# WKUP_CTRL_MMR0_CFG0 register map
Vendor: Texas Instruments
Peripheral module from a debugger description file (folder J7_AHP).
Registers are 32-bit, read-write, reset 0x0 unless marked. A register's access mark holds for its fields unless they carry their own. Offsets are as the file gives them; lines under a group give offsets from that group; [hi:lo] are bit positions; {n}, {i} and the like mark numbered series; 'fields as' and 'values as' point back to an identical list; <NAME> marks a mode.

## WKUP_CTRL_MMR0_CFG0 (part 1 of 11)
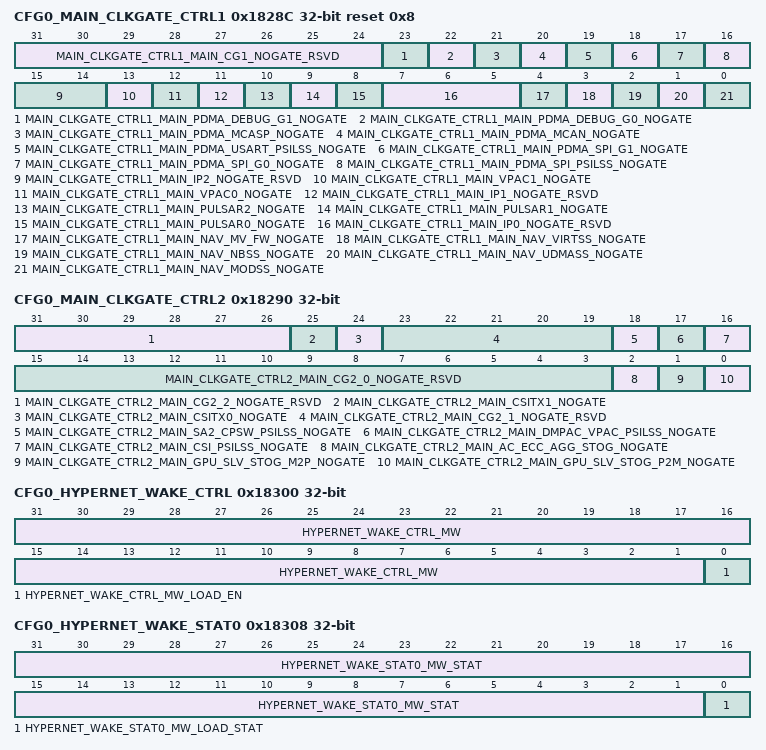
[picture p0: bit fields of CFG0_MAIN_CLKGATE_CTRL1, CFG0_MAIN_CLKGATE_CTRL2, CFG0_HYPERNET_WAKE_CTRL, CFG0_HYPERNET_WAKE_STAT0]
0x1828C CFG0_MAIN_CLKGATE_CTRL1 reset 0x8 — Controls the power clock gating feature of MAIN domain modules and busses
  [31:24] MAIN_CLKGATE_CTRL1_MAIN_CG1_NOGATE_RSVD — MAIN PDMA clock gate disable. These bits should remain unchanged (written only with their default value) to maintain compatibility with future devices. 0 - Clocks are gated on idle for power savings 1 - Clocks are not gated on idle, power saving disabled
  [23] MAIN_CLKGATE_CTRL1_MAIN_PDMA_DEBUG_G1_NOGATE — MAIN domain PDMA Debug_G1 clock gate disable. 0 - Clocks are gated on idle for power savings 1 - Clocks are not gated on idle, power saving disabled
  [22] MAIN_CLKGATE_CTRL1_MAIN_PDMA_DEBUG_G0_NOGATE — MAIN domain PDMA Debug_G0 clock gate disable. 0 - Clocks are gated on idle for power savings 1 - Clocks are not gated on idle, power saving disabled
  [21] MAIN_CLKGATE_CTRL1_MAIN_PDMA_MCASP_NOGATE — MAIN domain PDMA MCASP clock gate disable. 0 - Clocks are gated on idle for power savings 1 - Clocks are not gated on idle, power saving disabled
  [20] MAIN_CLKGATE_CTRL1_MAIN_PDMA_MCAN_NOGATE — MAIN domain PDMA MCAN clock gate disable. 0 - Clocks are gated on idle for power savings 1 - Clocks are not gated on idle, power saving disabled
  [19] MAIN_CLKGATE_CTRL1_MAIN_PDMA_USART_PSILSS_NOGATE — MAIN domain PDMA USART PSILSS clock gate disable. 0 - Clocks are gated on idle for power savings 1 - Clocks are not gated on idle, power saving disabled
  [18] MAIN_CLKGATE_CTRL1_MAIN_PDMA_SPI_G1_NOGATE — MAIN domain PDMA SPI_G1 clock gate disable. 0 - Clocks are gated on idle for power savings 1 - Clocks are not gated on idle, power saving disabled
  [17] MAIN_CLKGATE_CTRL1_MAIN_PDMA_SPI_G0_NOGATE — MAIN domain PDMA SPI_G0 clock gate disable. 0 - Clocks are gated on idle for power savings 1 - Clocks are not gated on idle, power saving disabled
  [16] MAIN_CLKGATE_CTRL1_MAIN_PDMA_SPI_PSILSS_NOGATE — MAIN domain PDMA SPI PSILSS clock gate disable. 0 - Clocks are gated on idle for power savings 1 - Clocks are not gated on idle, power saving disabled
  [15:14] MAIN_CLKGATE_CTRL1_MAIN_IP2_NOGATE_RSVD — MAIN IP reserved clock gate disable. These bits should remain unchanged (written only with their default value) to maintain compatibility with future devices. 0 - Clocks are gated on idle for power savings 1 - Clocks are not gated on idle, power saving disabled
  [13] MAIN_CLKGATE_CTRL1_MAIN_VPAC1_NOGATE — MAIN domain VPAC 1 clock gate disable. 0 - Clocks are gated on idle for power savings 1 - Clocks are not gated on idle, power saving disabled
  [12] MAIN_CLKGATE_CTRL1_MAIN_VPAC0_NOGATE — MAIN domain VPAC 0 clock gate disable. 0 - Clocks are gated on idle for power savings 1 - Clocks are not gated on idle, power saving disabled
  [11] MAIN_CLKGATE_CTRL1_MAIN_IP1_NOGATE_RSVD — MAIN IP reserved clock gate disable. These bits should remain unchanged (written only with their default value) to maintain compatibility with future devices. 0 - Clocks are gated on idle for power savings 1 - Clocks are not gated on idle, power saving disabled
  [10] MAIN_CLKGATE_CTRL1_MAIN_PULSAR2_NOGATE — MAIN domain Pulsar 2 clock gate disable. 0 - Clocks are gated on idle for power savings 1 - Clocks are not gated on idle, power saving disabled
  [9] MAIN_CLKGATE_CTRL1_MAIN_PULSAR1_NOGATE — MAIN domain Pulsar 1 clock gate disable. 0 - Clocks are gated on idle for power savings 1 - Clocks are not gated on idle, power saving disabled
  [8] MAIN_CLKGATE_CTRL1_MAIN_PULSAR0_NOGATE — MAIN domain Pulsar 0 clock gate disable. 0 - Clocks are gated on idle for power savings 1 - Clocks are not gated on idle, power saving disabled
  [7:5] MAIN_CLKGATE_CTRL1_MAIN_IP0_NOGATE_RSVD — MAIN IP reserved clock gate disable. These bits should remain unchanged (written only with their default value) to maintain compatibility with future devices. 0 - Clocks are gated on idle for power savings 1 - Clocks are not gated on idle, power saving disabled
  [4] MAIN_CLKGATE_CTRL1_MAIN_NAV_MV_FW_NOGATE — MAIN NavSS Mod/Virt Firewall interface clock gate disable. 0 - Clocks are gated on idle for power savings 1 - Clocks are not gated on idle, power saving disabled
  [3] MAIN_CLKGATE_CTRL1_MAIN_NAV_VIRTSS_NOGATE — MAIN NavSS VIRTSS interface clock gate disable. 0 - Clocks are gated on idle for power savings 1 - Clocks are not gated on idle, power saving disabled
  [2] MAIN_CLKGATE_CTRL1_MAIN_NAV_NBSS_NOGATE — MAIN NavSS NB interface clock gate disable. 0 - Clocks are gated on idle for power savings 1 - Clocks are not gated on idle, power saving disabled
  [1] MAIN_CLKGATE_CTRL1_MAIN_NAV_UDMASS_NOGATE — Main NavSS UDMA interface clock gate disable. 0 - Clocks are gated on idle for power savings 1 - Clocks are not gated on idle, power saving disabled
  [0] MAIN_CLKGATE_CTRL1_MAIN_NAV_MODSS_NOGATE — MAIN NavSS MODSS interface clock gate disable. 0 - Clocks are gated on idle for power savings 1 - Clocks are not gated on idle, power saving disabled
0x18290 CFG0_MAIN_CLKGATE_CTRL2 — Controls the power clock gating feature of MAIN domain modules and busses
  [31:26] MAIN_CLKGATE_CTRL2_MAIN_CG2_2_NOGATE_RSVD — MAIN domain spare clock gate disable. These bits should remain unchanged (written only with their default value) to maintain compatibility with future devices. 0 - Clocks are gated on idle for power savings 1 - Clocks are not gated on idle, power saving disabled
  [25] MAIN_CLKGATE_CTRL2_MAIN_CSITX1_NOGATE — MAIN domain CSI_TX1 clock gate disable. 0 - Clocks are gated on idle for power savings 1 - Clocks are not gated on idle, power saving disabled
  [24] MAIN_CLKGATE_CTRL2_MAIN_CSITX0_NOGATE — MAIN domain CSI_TX0 clock gate disable. 0 - Clocks are gated on idle for power savings 1 - Clocks are not gated on idle, power saving disabled
  [23:19] MAIN_CLKGATE_CTRL2_MAIN_CG2_1_NOGATE_RSVD — MAIN domain spare clock gate disable. These bits should remain unchanged (written only with their default value) to maintain compatibility with future devices. 0 - Clocks are gated on idle for power savings 1 - Clocks are not gated on idle, power saving disabled
  [18] MAIN_CLKGATE_CTRL2_MAIN_SA2_CPSW_PSILSS_NOGATE — MAIN domain SA2_UL/SPCW PSILSS clock gate disable. 0 - Clocks are gated on idle for power savings 1 - Clocks are not gated on idle, power saving disabled
  [17] MAIN_CLKGATE_CTRL2_MAIN_DMPAC_VPAC_PSILSS_NOGATE — MAIN domain DMPAC/VPAC PSILSS clock gate disable. 0 - Clocks are gated on idle for power savings 1 - Clocks are not gated on idle, power saving disabled
  [16] MAIN_CLKGATE_CTRL2_MAIN_CSI_PSILSS_NOGATE — MAIN domain CSI PSILSS clock gate disable. 0 - Clocks are gated on idle for power savings 1 - Clocks are not gated on idle, power saving disabled
  [15:3] MAIN_CLKGATE_CTRL2_MAIN_CG2_0_NOGATE_RSVD — MAIN domain spare clock gate disable. These bits should remain unchanged (written only with their default value) to maintain compatibility with future devices. 0 - Clocks are gated on idle for power savings 1 - Clocks are not gated on idle, power saving disabled
  [2] MAIN_CLKGATE_CTRL2_MAIN_AC_ECC_AGG_STOG_NOGATE — MAIN domain ac ECC aggregator Slave Timeout Gasket (main_ac_ecc_aggr_stog) clock gate disable. 0 - Clocks are gated on idle for power savings 1 - Clocks are not gated on idle, power saving disabled
  [1] MAIN_CLKGATE_CTRL2_MAIN_GPU_SLV_STOG_M2P_NOGATE — MAIN domain GPU Slave Timeout Gasket output (main_gpu_slv_stog_m2p_pwr_dis) clock gate disable. 0 - Clocks are gated on idle for power savings 1 - Clocks are not gated on idle, power saving disabled
  [0] MAIN_CLKGATE_CTRL2_MAIN_GPU_SLV_STOG_P2M_NOGATE — MAIN domain GPU Slave Timeout Gasket input (main_gpu_slv_stog_p2m_pwr_dis) clock gate disable. 0 - Clocks are gated on idle for power savings 1 - Clocks are not gated on idle, power saving disabled
0x18294 CFG0_MAIN_CLKGATE_CTRL3 — Controls the power clock gating feature of MAIN domain modules and busses
  [31:0] MAIN_CLKGATE_CTRL3_MAIN_CG3_NOGATE_RSVD — MAIN domain spare clock gate disable. These bits should remain unchanged (written only with their default value) to maintain compatibility with future devices. 0 - Clocks are gated on idle for power savings 1 - Clocks are not gated on idle, power saving disabled
0x18300 CFG0_HYPERNET_WAKE_CTRL — Controls the operation of IO wakeup on the MAIN HYPERNET pins
  [31:1] HYPERNET_WAKE_CTRL_MW — HYPERNET IO magic word. This 31-bit value that enables placing of the HYPERNET I/Os into isolation for daisy-chain wakeup operation. 0x2AAAAAAA - Magic word value to enable isolation when qualified with mw_load bit Others - Any other value will prevent isolation when mw_load transitions from 0 to 1.
  [0] HYPERNET_WAKE_CTRL_MW_LOAD_EN — Magic word load enableSetting this bit to 1 loads and locks the mw field for HYPERNET IO isolation. If the mw field matches the magic word value then the value is latched into the HYPERNET IO voltage domain and HYPERNET IO isolation is enabled. 0 - Unlock and do not load mw value for comparison 1 - Load and lock mw for magic word value comparison
0x18308 CFG0_HYPERNET_WAKE_STAT0 ro — Provides the status of MAIN HYPERNET_WAKE control bits
  [31:1] HYPERNET_WAKE_STAT0_MW_STAT — HYPERNET magic word statusIndicates the latched value of the mw field.
  [0] HYPERNET_WAKE_STAT0_MW_LOAD_STAT — Magic word load status.Indicates the latched value of the mw_load_en bit
0x1830C CFG0_HYPERNET_WAKE_STAT1 ro — Provides MAIN HYPERNET IO isolation status
  [0] HYPERNET_WAKE_STAT1_HYPERNET_IO_MODE — Indicates if HYPERNET IO wakeup mode is enabled. 0 - Not enabled (load_en not set or mw doesn't match magic word) 1 - HYPERNET IO mode enabled
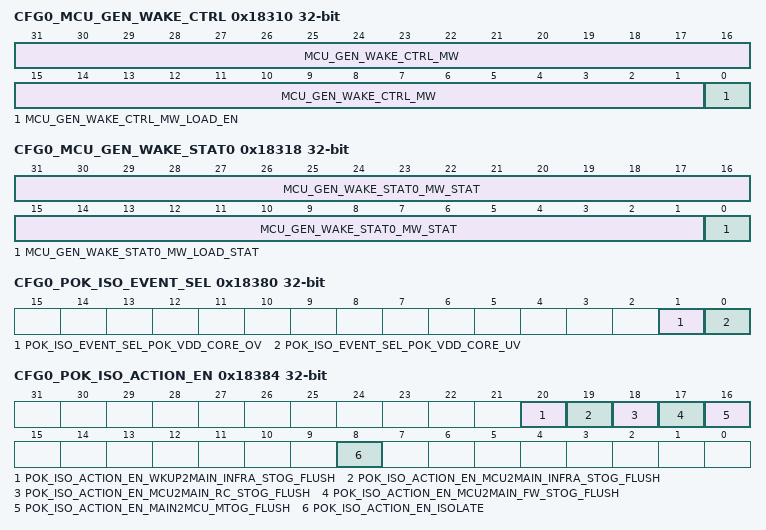
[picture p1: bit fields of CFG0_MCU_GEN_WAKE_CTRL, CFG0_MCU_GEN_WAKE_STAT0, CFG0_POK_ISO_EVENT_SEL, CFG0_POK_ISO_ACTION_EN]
0x18310 CFG0_MCU_GEN_WAKE_CTRL — Controls the operation of IO wakeup on the MCU_GENERAL pins
  [31:1] MCU_GEN_WAKE_CTRL_MW — MCU_GENERAL IO magic word. This 31-bit value that enables placing of the MCU_GENERAL I/Os into isolation for daisy-chain wakeup operation. 0x2AAAAAAA - Magic word value to enable isolation when qualified with mw_load bit Others - Any other value will prevent isolation when mw_load transitions from 0 to 1.
  [0] MCU_GEN_WAKE_CTRL_MW_LOAD_EN — Magic word load enableSetting this bit to 1 loads and locks the mw field for MCU_GENERAL IO isolation. If the mw field matches the magic word value then the value is latched into the MCU_GENERAL IO voltage domain and MCU_GENERAL IO isolation is enabled. 0 - Unlock and do not load mw value for comparison 1 - Load and lock mw for magic word value comparison
0x18318 CFG0_MCU_GEN_WAKE_STAT0 ro — Provides the status of MCU_GEN_WAKE control bits
  [31:1] MCU_GEN_WAKE_STAT0_MW_STAT — MCU_GENERAL magic word statusIndicates the latched value of the mw field.
  [0] MCU_GEN_WAKE_STAT0_MW_LOAD_STAT — Magic word load status.Indicates the latched value of the mw_load_en bit
0x1831C CFG0_MCU_GEN_WAKE_STAT1 ro — Provides MCU_GENERAL IO isolation status
  [0] MCU_GEN_WAKE_STAT1_MCU_GEN_IO_MODE — Indicates if MCU_GENERAL IO wakeup mode is enabled. 0 - Not enabled (load_en not set or mw doesn't match magic word) 1 - MCU_GENERAL IO mode enabled
0x18380 CFG0_POK_ISO_EVENT_SEL — Determines which POK events activate isolation features
  [1] POK_ISO_EVENT_SEL_POK_VDD_CORE_OV — VDD_CORE overvoltage detection triggers enabled isolation actions
  [0] POK_ISO_EVENT_SEL_POK_VDD_CORE_UV — VDD_CORE undervoltage detection triggers enabled isolation actions
0x18384 CFG0_POK_ISO_ACTION_EN — Selects which isolation actions to perform when POK events as selected in POK_ISO_EVENT_SEL occur
  [20] POK_ISO_ACTION_EN_WKUP2MAIN_INFRA_STOG_FLUSH — WKUP to Main INFRA slave timeout gasket flush enable: 0 - Enabled POK events have no effect on this gasket 1 - Enabled POK events will assert the flush for this gasket
  [19] POK_ISO_ACTION_EN_MCU2MAIN_INFRA_STOG_FLUSH — MCU to Main INFRA slave timeout gasket flush enable: 0 - Enabled POK events have no effect on this gasket 1 - Enabled POK events will assert the flush for this gasket
  [18] POK_ISO_ACTION_EN_MCU2MAIN_RC_STOG_FLUSH — MCU to Main RC slave timeout gasket flush enable: 0 - Enabled POK events have no effect on this gasket 1 - Enabled POK events will assert the flush for this gasket
  [17] POK_ISO_ACTION_EN_MCU2MAIN_FW_STOG_FLUSH — MCU to Main FW slave timeout gasket flush enable: 0 - Enabled POK events have no effect on this gasket 1 - Enabled POK events will assert the flush for this gasket
  [16] POK_ISO_ACTION_EN_MAIN2MCU_MTOG_FLUSH — MAIN to MCU master timeout gasket flush enable: 0 - Enabled POK events have no effect on this gasket 1 - Enabled POK events will assert the flush for this gasket
  [8] POK_ISO_ACTION_EN_ISOLATE — If enabled, the isolate signal will be asserted after all enabled flush signals have been asserted for 4 of their respective time-out gasket clocks when any selected POK event occurs. 0 - Isolation is not asserted on selected POK event 1 - Isolation signal is asserted on selected POK event after enabled TOG flush
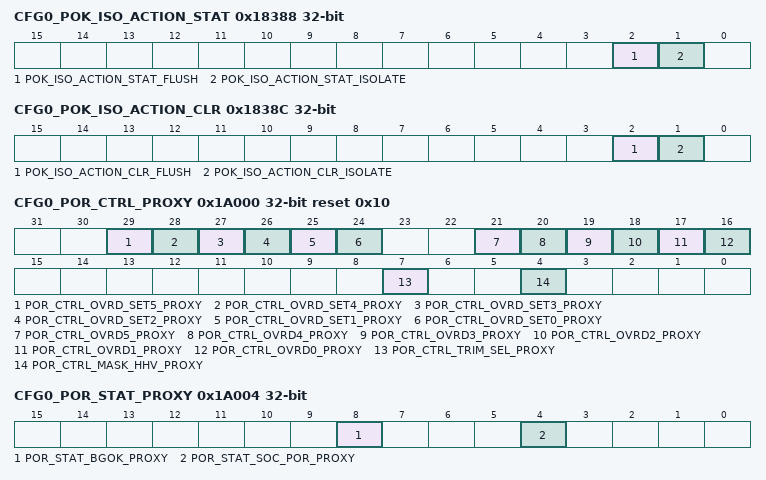
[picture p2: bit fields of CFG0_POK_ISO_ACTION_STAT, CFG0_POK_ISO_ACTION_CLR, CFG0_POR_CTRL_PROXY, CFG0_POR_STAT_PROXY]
0x18388 CFG0_POK_ISO_ACTION_STAT ro — Indicates the status of enabled POK isolation actions
  [2] POK_ISO_ACTION_STAT_FLUSH — POK activated timeout gasket flush statusThis signal will remain asserted until a 1 is written to the POK_ISO_ACTION_CLR_flush bit. 0 - No gasket flush is being asserted by enabled POK event 1 - Enabled gasket flush signals are being asserted due to an enabled POK event
  [1] POK_ISO_ACTION_STAT_ISOLATE — POK activated Isolate statusThis signal will remain asserted until a 1 is written to the POK_ISO_ACTION_CLR_isolate bit. 0 - No isolate is being asserted by enabled POK event 1 - Isolate signal is being asserted due to an enabled POK event
0x1838C CFG0_POK_ISO_ACTION_CLR — Selects which active POK isolation actions to clear
  [2] POK_ISO_ACTION_CLR_FLUSH — POK activated timeout gasket flush clearAlways read as 0. Writing 1 deasserts POK activated timeot gasket flush signals. 0 - Writing 0 has no effect. Bit always reads as 0 1 - Deassert gasket flush signals. Bit will clear to 0 after write.
  [1] POK_ISO_ACTION_CLR_ISOLATE — POK activated isolate clearAlways read as 0. Writing 1 deasserts POK activated isolate signal. 0 - Writing 0 has no effect. Bit always reads as 0 1 - Deassert isolate signal. Bit will clear to 0 after write.
{0x19100+4i} CFG0_CLAIMREG_P6_R{i}_READONLY ro (i=0..7)
  [31:0] CLAIMREG_P6_R{i}_READONLY — Claim bits for Partition 6
0x1A000 CFG0_POR_CTRL_PROXY reset 0x10 — Configures POR module reset behavior
  [29] POR_CTRL_OVRD_SET5_PROXY — Reserved override set
  [28] POR_CTRL_OVRD_SET4_PROXY — POKLVB override set
  [27] POR_CTRL_OVRD_SET3_PROXY — POKLVA override set
  [26] POR_CTRL_OVRD_SET2_PROXY — POKHV override set
  [25] POR_CTRL_OVRD_SET1_PROXY — BGOK override set
  [24] POR_CTRL_OVRD_SET0_PROXY — PORHV override set
  [21] POR_CTRL_OVRD5_PROXY — Reserved override enable
  [20] POR_CTRL_OVRD4_PROXY — POKLVB override enable
  [19] POR_CTRL_OVRD3_PROXY — POKLVA override enable
  [18] POR_CTRL_OVRD2_PROXY — POKHV override enable
  [17] POR_CTRL_OVRD1_PROXY — BGOK override enable
  [16] POR_CTRL_OVRD0_PROXY — PORHV override enable
  [7] POR_CTRL_TRIM_SEL_PROXY — POR Trim Select 0 - Trim selections for Bandgap and POKs come from HHV defaults 1 - Trim selections for Bandgap and POKs come from POR_BANDGAP_CTRL and POR_POKxxx_CTRL registers
  [4] POR_CTRL_MASK_HHV_PROXY — Mask HHV/SOC_PORz outputs when applying new trim values
0x1A004 CFG0_POR_STAT_PROXY ro — Shows POR module status
  [8] POR_STAT_BGOK_PROXY — Bandgap OK status
  [4] POR_STAT_SOC_POR_PROXY — POR module status 0 - Module is in functional mode 1 - Module is in reset mode
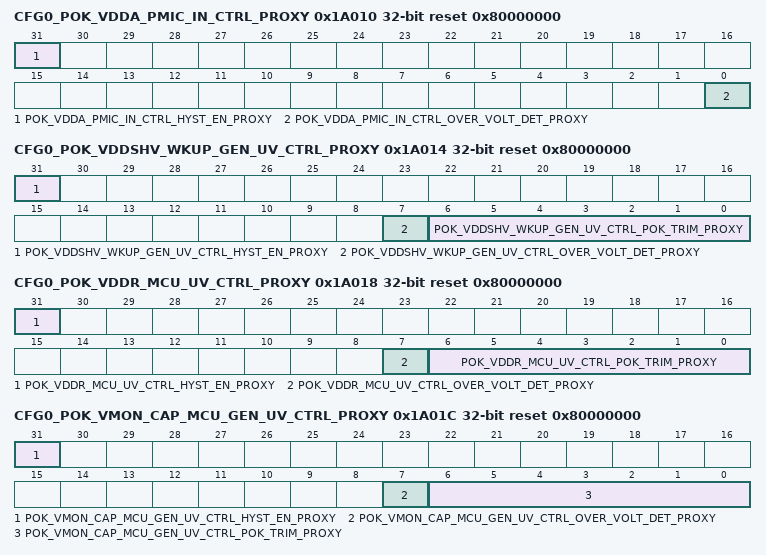
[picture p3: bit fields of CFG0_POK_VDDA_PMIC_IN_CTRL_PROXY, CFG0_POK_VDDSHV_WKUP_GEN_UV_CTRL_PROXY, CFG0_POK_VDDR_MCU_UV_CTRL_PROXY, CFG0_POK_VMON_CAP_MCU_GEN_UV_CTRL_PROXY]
0x1A010 CFG0_POK_VDDA_PMIC_IN_CTRL_PROXY reset 0x80000000 — Controls operation of the VDDA_PMIC_IN POK module
  [31] POK_VDDA_PMIC_IN_CTRL_HYST_EN_PROXY — Enable POK hysteresis
  [0] POK_VDDA_PMIC_IN_CTRL_OVER_VOLT_DET_PROXY — Over / under voltage detection mode 0 - Under voltage detection 1 - Over voltage detection
0x1A014 CFG0_POK_VDDSHV_WKUP_GEN_UV_CTRL_PROXY reset 0x80000000 — Controls operation of the VDDSHV_WKUP_GENERAL POK undervoltage detection
  [31] POK_VDDSHV_WKUP_GEN_UV_CTRL_HYST_EN_PROXY — Enable POK hysteresis
  [7] POK_VDDSHV_WKUP_GEN_UV_CTRL_OVER_VOLT_DET_PROXY — Over / under voltage detection mode 0 - Under voltage detection 1 - Over voltage detection
  [6:0] POK_VDDSHV_WKUP_GEN_UV_CTRL_POK_TRIM_PROXY — POK trim bits. These bits are used to trim the comparator threshold voltage. See POK spec and J7 efuse spec for details
0x1A018 CFG0_POK_VDDR_MCU_UV_CTRL_PROXY reset 0x80000000 — Controls operation of the VDDR_MCU POK undervoltage detection
  [31] POK_VDDR_MCU_UV_CTRL_HYST_EN_PROXY — Enable POK hysteresis
  [7] POK_VDDR_MCU_UV_CTRL_OVER_VOLT_DET_PROXY — Over / under voltage detection mode 0 - Under voltage detection 1 - Over voltage detection
  [6:0] POK_VDDR_MCU_UV_CTRL_POK_TRIM_PROXY — POK trim bits. These bits are used to trim the comparator threshold voltage. See POK spec and J7 efuse spec for details
0x1A01C CFG0_POK_VMON_CAP_MCU_GEN_UV_CTRL_PROXY reset 0x80000000 — Controls operation of the VMON_CAP_MCU_GENERAL POK undervoltage detection
  [31] POK_VMON_CAP_MCU_GEN_UV_CTRL_HYST_EN_PROXY — Enable POK hysteresis
  [7] POK_VMON_CAP_MCU_GEN_UV_CTRL_OVER_VOLT_DET_PROXY — Over / under voltage detection mode 0 - Under voltage detection 1 - Over voltage detection
  [6:0] POK_VMON_CAP_MCU_GEN_UV_CTRL_POK_TRIM_PROXY — POK trim bits. These bits are used to trim the comparator threshold voltage. See POK spec and efuse spec for details
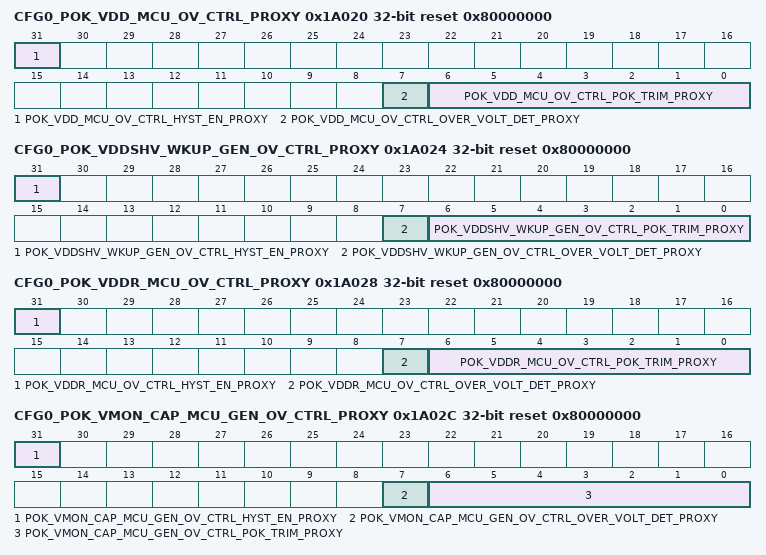
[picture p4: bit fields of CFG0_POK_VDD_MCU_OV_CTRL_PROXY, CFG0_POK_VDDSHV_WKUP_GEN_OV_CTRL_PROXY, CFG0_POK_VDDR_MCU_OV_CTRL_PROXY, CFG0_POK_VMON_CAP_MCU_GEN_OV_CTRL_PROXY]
0x1A020 CFG0_POK_VDD_MCU_OV_CTRL_PROXY reset 0x80000000 — Controls operation of the VDD_MCU overvoltage POK module
  [31] POK_VDD_MCU_OV_CTRL_HYST_EN_PROXY — Enable POK hysteresis
  [7] POK_VDD_MCU_OV_CTRL_OVER_VOLT_DET_PROXY — Over / under voltage detection mode 0 - Under voltage detection 1 - Over voltage detection
  [6:0] POK_VDD_MCU_OV_CTRL_POK_TRIM_PROXY — POK trim bits. These bits are used to trim the comparator threshold voltage. See POK spec and J7 efuse spec for details
0x1A024 CFG0_POK_VDDSHV_WKUP_GEN_OV_CTRL_PROXY reset 0x80000000 — Controls operation of the VDDSHV_WKUP_GENERAL POK overvoltage detection
  [31] POK_VDDSHV_WKUP_GEN_OV_CTRL_HYST_EN_PROXY — Enable POK hysteresis
  [7] POK_VDDSHV_WKUP_GEN_OV_CTRL_OVER_VOLT_DET_PROXY — Over / under voltage detection mode 0 - Under voltage detection 1 - Over voltage detection
  [6:0] POK_VDDSHV_WKUP_GEN_OV_CTRL_POK_TRIM_PROXY — POK trim bits. These bits are used to trim the comparator threshold voltage. See POK spec and J7 efuse spec for details
0x1A028 CFG0_POK_VDDR_MCU_OV_CTRL_PROXY reset 0x80000000 — Controls operation of the VDDR_MCU POK overvoltage detection
  [31] POK_VDDR_MCU_OV_CTRL_HYST_EN_PROXY — Enable POK hysteresis
  [7] POK_VDDR_MCU_OV_CTRL_OVER_VOLT_DET_PROXY — Over / under voltage detection mode 0 - Under voltage detection 1 - Over voltage detection
  [6:0] POK_VDDR_MCU_OV_CTRL_POK_TRIM_PROXY — POK trim bits. These bits are used to trim the comparator threshold voltage. See POK spec and J7 efuse spec for details
0x1A02C CFG0_POK_VMON_CAP_MCU_GEN_OV_CTRL_PROXY reset 0x80000000 — Controls operation of the VMON_CAP_MCU_GENERAL POK overvoltage detection
  [31] POK_VMON_CAP_MCU_GEN_OV_CTRL_HYST_EN_PROXY — Enable POK hysteresis
  [7] POK_VMON_CAP_MCU_GEN_OV_CTRL_OVER_VOLT_DET_PROXY — Over / under voltage detection mode 0 - Under voltage detection 1 - Over voltage detection
  [6:0] POK_VMON_CAP_MCU_GEN_OV_CTRL_POK_TRIM_PROXY — POK trim bits. These bits are used to trim the comparator threshold voltage. See POK spec and efuse spec for details
0x1A070 CFG0_MAIN_VDOM_CTRL_PROXY — Provides MAIN voltage domain isolation for deep sleep operation
  [0] MAIN_VDOM_CTRL_MAIN_VD_OFF_PROXY — MAIN deep sleep isolation enable. This bit should be set prior to powering off the MAIN voltage domain to ensure proper signal isolation.
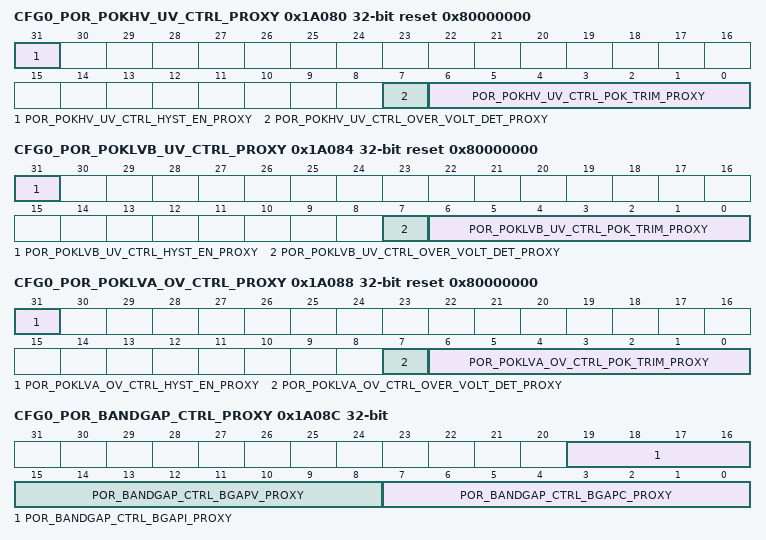
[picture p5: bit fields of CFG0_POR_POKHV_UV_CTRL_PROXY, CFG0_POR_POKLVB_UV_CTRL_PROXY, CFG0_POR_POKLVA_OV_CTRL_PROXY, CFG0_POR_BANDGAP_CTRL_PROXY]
0x1A080 CFG0_POR_POKHV_UV_CTRL_PROXY reset 0x80000000 — Controls operation of the 1.8V VDDA_MCU undervoltage POK within the POR
  [31] POR_POKHV_UV_CTRL_HYST_EN_PROXY — Enable POK hysteresis
  [7] POR_POKHV_UV_CTRL_OVER_VOLT_DET_PROXY — Over / under voltage detection mode 0 - Under voltage detection 1 - Over voltage detection
  [6:0] POR_POKHV_UV_CTRL_POK_TRIM_PROXY — POK trim bits. These bits are used to trim the comparator threshold voltage. See POK spec and J7 efuse spec for details
0x1A084 CFG0_POR_POKLVB_UV_CTRL_PROXY reset 0x80000000 — Controls operation of the VDD_MCU undervoltage POK within the POR
  [31] POR_POKLVB_UV_CTRL_HYST_EN_PROXY — Enable POK hysteresis
  [7] POR_POKLVB_UV_CTRL_OVER_VOLT_DET_PROXY — Over / under voltage detection mode 0 - Under voltage detection 1 - Over voltage detection
  [6:0] POR_POKLVB_UV_CTRL_POK_TRIM_PROXY — POK trim bits. These bits are used to trim the comparator threshold voltage. See POK spec and J7 efuse spec for details
0x1A088 CFG0_POR_POKLVA_OV_CTRL_PROXY reset 0x80000000 — Controls operation of the 1.8V VDDA_MCU overvoltage POK within the POR
  [31] POR_POKLVA_OV_CTRL_HYST_EN_PROXY — Enable POK hysteresis
  [7] POR_POKLVA_OV_CTRL_OVER_VOLT_DET_PROXY — Over / under voltage detection mode 0 - Under voltage detection 1 - Over voltage detection
  [6:0] POR_POKLVA_OV_CTRL_POK_TRIM_PROXY — POK trim bits. These bits are used to trim the comparator threshold voltage. See POK spec and J7 efuse spec for details
0x1A08C CFG0_POR_BANDGAP_CTRL_PROXY — Controls the operation of the bandgap module within the POR
  [19:16] POR_BANDGAP_CTRL_BGAPI_PROXY — Bandgap output current trim bits
  [15:8] POR_BANDGAP_CTRL_BGAPV_PROXY — Bandgap output voltage magnitude trim bits
  [7:0] POR_BANDGAP_CTRL_BGAPC_PROXY — Bandgap slope trim bits. Bit7 is used to calculate the offset
0x1A0A0 CFG0_TEMP_DIODE_TRIM_PROXY — Trims the silicon junction temperature diode calculation
  [13:0] TEMP_DIODE_TRIM_TRIM_PROXY — Sets the diode non-ideality factor (n), starting from 100th place decimal and going down
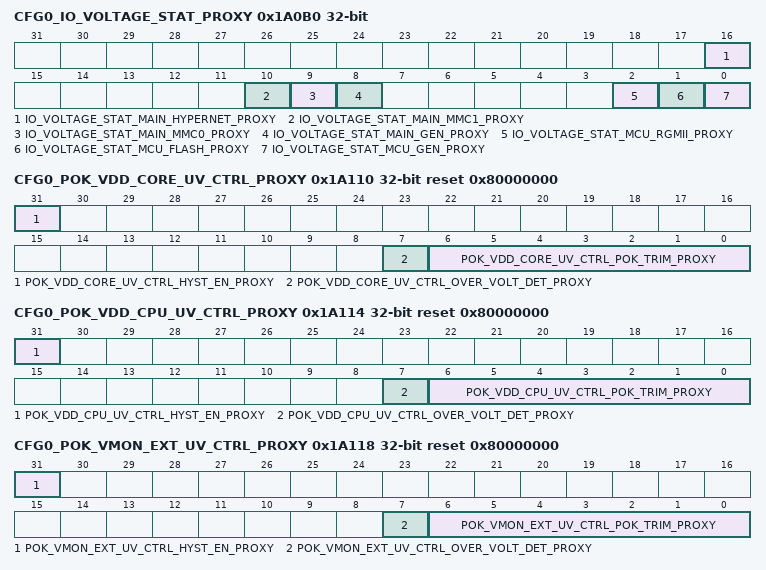
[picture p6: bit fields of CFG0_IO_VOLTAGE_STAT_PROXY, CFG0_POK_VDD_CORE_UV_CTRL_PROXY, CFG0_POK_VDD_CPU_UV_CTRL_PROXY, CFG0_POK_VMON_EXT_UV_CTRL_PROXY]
0x1A0B0 CFG0_IO_VOLTAGE_STAT_PROXY ro — Indicates the I/O voltage of each LVCMOS dual I/O group
  [16] IO_VOLTAGE_STAT_MAIN_HYPERNET_PROXY — Indicates the voltage for the HYPERNET I/O group 0 - I/O group is set for 3.3 V 1 - I/O group is set for 1.8 V
  [10] IO_VOLTAGE_STAT_MAIN_MMC1_PROXY — Indicates the voltage for the MMC1 I/O group 0 - I/O group is set for 3.3 V 1 - I/O group is set for 1.8 V
  [9] IO_VOLTAGE_STAT_MAIN_MMC0_PROXY — Indicates the voltage for the MMC0 I/O group 0 - I/O group is set for 3.3 V 1 - I/O group is set for 1.8 V
  [8] IO_VOLTAGE_STAT_MAIN_GEN_PROXY — Indicates the voltage for the General I/O group 0 - I/O group is set for 3.3 V 1 - I/O group is set for 1.8 V
  [2] IO_VOLTAGE_STAT_MCU_RGMII_PROXY — Indicates the voltage for the MCU CPSW2G RGMII I/O group 0 - I/O group is set for 3.3 V 1 - I/O group is set for 1.8 V
  [1] IO_VOLTAGE_STAT_MCU_FLASH_PROXY — Indicates the voltage for the MCU Flash I/O group 0 - I/O group is set for 3.3 V 1 - I/O group is set for 1.8 V
  [0] IO_VOLTAGE_STAT_MCU_GEN_PROXY — Indicates the voltage for the MCU General I/O group 0 - I/O group is set for 3.3 V 1 - I/O group is set for 1.8 V
0x1A104 CFG0_MAIN_POR_TO_CTRL_PROXY — Indicates the MAIN PORz timeout period
  [2:0] MAIN_POR_TO_CTRL_TIMEOUT_PER_PROXY — MAIN PORz hardware timeout period.During normal operation, the assertion of a MAIN Domain PORz generates a reset request interrupt to the DMSC. The DMSC then performs steps to properly isolate the MAIN Domain before the actual reset is performed. A hardware timeout mechanism is provided to ensure that the PORz gets propagated to the MAIN Domain in the event that a error prevents the DMSC from completing the reset isolation. Field values (Others are reserved): 3'b000 - Immediate 3'b001 - 100 microsec 3'b010 - 200 microsec 3'b011 - 300 microsec 3'b100 - 400 microsec 3'b101 - 500 microsec
0x1A110 CFG0_POK_VDD_CORE_UV_CTRL_PROXY reset 0x80000000 — Controls operation of the VDD_CORE POK undervoltage detection
  [31] POK_VDD_CORE_UV_CTRL_HYST_EN_PROXY — Enable POK hysteresis
  [7] POK_VDD_CORE_UV_CTRL_OVER_VOLT_DET_PROXY — Over / under voltage detection mode 0 - Under voltage detection 1 - Over voltage detection
  [6:0] POK_VDD_CORE_UV_CTRL_POK_TRIM_PROXY — POK trim bits. These bits are used to trim the comparator threshold voltage. See POK spec and efuse spec for details
0x1A114 CFG0_POK_VDD_CPU_UV_CTRL_PROXY reset 0x80000000 — Controls operation of the VDD_CPU POK undervoltage detection
  [31] POK_VDD_CPU_UV_CTRL_HYST_EN_PROXY — Enable POK hysteresis
  [7] POK_VDD_CPU_UV_CTRL_OVER_VOLT_DET_PROXY — Over / under voltage detection mode 0 - Under voltage detection 1 - Over voltage detection
  [6:0] POK_VDD_CPU_UV_CTRL_POK_TRIM_PROXY — POK trim bits. These bits are used to trim the comparator threshold voltage. See POK spec and efuse spec for details
0x1A118 CFG0_POK_VMON_EXT_UV_CTRL_PROXY reset 0x80000000 — Controls operation of the VMON_EXTC POK undervoltage detection
  [31] POK_VMON_EXT_UV_CTRL_HYST_EN_PROXY — Enable POK hysteresis
  [7] POK_VMON_EXT_UV_CTRL_OVER_VOLT_DET_PROXY — Over / under voltage detection mode 0 - Under voltage detection 1 - Over voltage detection
  [6:0] POK_VMON_EXT_UV_CTRL_POK_TRIM_PROXY — POK trim bits. These bits are used to trim the comparator threshold voltage. See POK spec and efuse spec for details
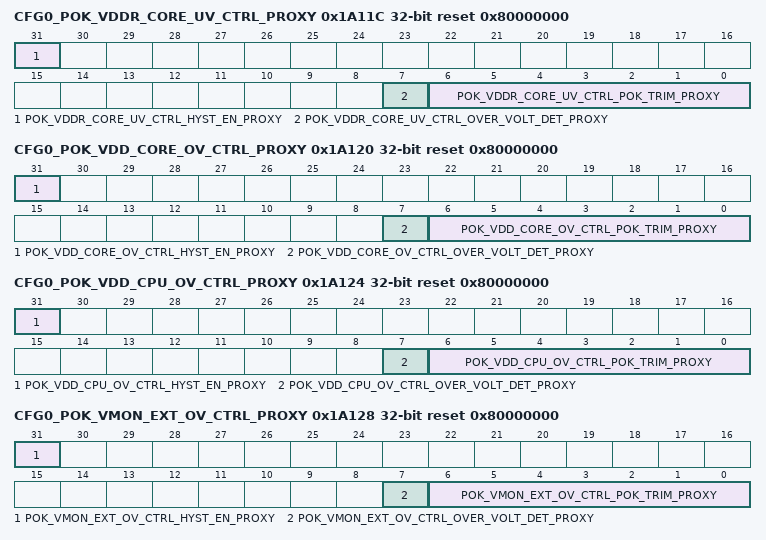
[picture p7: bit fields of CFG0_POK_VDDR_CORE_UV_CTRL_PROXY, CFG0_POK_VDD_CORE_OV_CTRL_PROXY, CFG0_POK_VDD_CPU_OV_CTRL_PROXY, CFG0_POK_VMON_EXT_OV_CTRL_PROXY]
0x1A11C CFG0_POK_VDDR_CORE_UV_CTRL_PROXY reset 0x80000000 — Controls operation of the VDDR_CORE POK undervoltage detection
  [31] POK_VDDR_CORE_UV_CTRL_HYST_EN_PROXY — Enable POK hysteresis
  [7] POK_VDDR_CORE_UV_CTRL_OVER_VOLT_DET_PROXY — Over / under voltage detection mode 0 - Under voltage detection 1 - Over voltage detection
  [6:0] POK_VDDR_CORE_UV_CTRL_POK_TRIM_PROXY — POK trim bits. These bits are used to trim the comparator threshold voltage. See POK spec and efuse spec for details
0x1A120 CFG0_POK_VDD_CORE_OV_CTRL_PROXY reset 0x80000000 — Controls operation of the VDD_CORE POK overvoltage detection
  [31] POK_VDD_CORE_OV_CTRL_HYST_EN_PROXY — Enable POK hysteresis
  [7] POK_VDD_CORE_OV_CTRL_OVER_VOLT_DET_PROXY — Over / under voltage detection mode 0 - Under voltage detection 1 - Over voltage detection
  [6:0] POK_VDD_CORE_OV_CTRL_POK_TRIM_PROXY — POK trim bits. These bits are used to trim the comparator threshold voltage. See POK spec and efuse spec for details
0x1A124 CFG0_POK_VDD_CPU_OV_CTRL_PROXY reset 0x80000000 — Controls operation of the VDD_CPU POK overvoltage detection
  [31] POK_VDD_CPU_OV_CTRL_HYST_EN_PROXY — Enable POK hysteresis
  [7] POK_VDD_CPU_OV_CTRL_OVER_VOLT_DET_PROXY — Over / under voltage detection mode 0 - Under voltage detection 1 - Over voltage detection
  [6:0] POK_VDD_CPU_OV_CTRL_POK_TRIM_PROXY — POK trim bits. These bits are used to trim the comparator threshold voltage. See POK spec and efuse spec for details
0x1A128 CFG0_POK_VMON_EXT_OV_CTRL_PROXY reset 0x80000000 — Controls operation of the VMON_EXT POK overvoltage detection
  [31] POK_VMON_EXT_OV_CTRL_HYST_EN_PROXY — Enable POK hysteresis
  [7] POK_VMON_EXT_OV_CTRL_OVER_VOLT_DET_PROXY — Over / under voltage detection mode 0 - Under voltage detection 1 - Over voltage detection
  [6:0] POK_VMON_EXT_OV_CTRL_POK_TRIM_PROXY — POK trim bits. These bits are used to trim the comparator threshold voltage. See POK spec and efuse spec for details
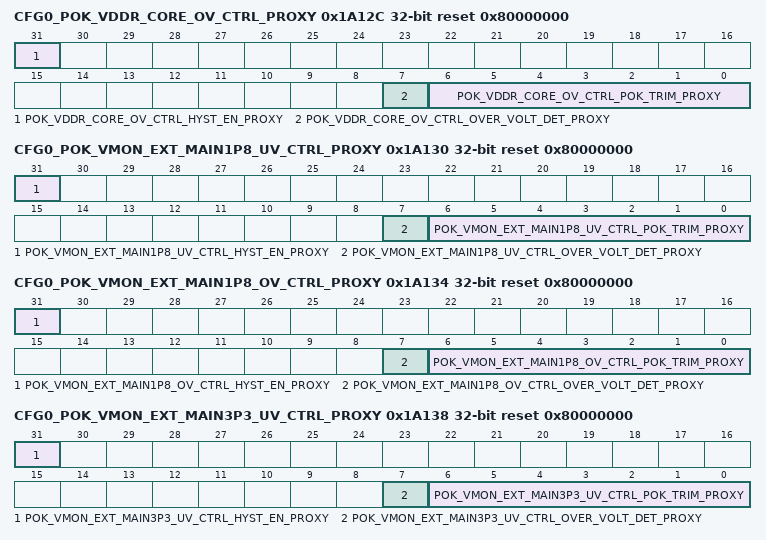
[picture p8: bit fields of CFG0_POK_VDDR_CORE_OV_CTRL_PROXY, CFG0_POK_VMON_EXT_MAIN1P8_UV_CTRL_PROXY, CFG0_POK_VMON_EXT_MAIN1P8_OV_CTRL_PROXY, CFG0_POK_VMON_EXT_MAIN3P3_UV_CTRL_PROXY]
0x1A12C CFG0_POK_VDDR_CORE_OV_CTRL_PROXY reset 0x80000000 — Controls operation of the VDDR_CORE POK overvoltage detection
  [31] POK_VDDR_CORE_OV_CTRL_HYST_EN_PROXY — Enable POK hysteresis
  [7] POK_VDDR_CORE_OV_CTRL_OVER_VOLT_DET_PROXY — Over / under voltage detection mode 0 - Under voltage detection 1 - Over voltage detection
  [6:0] POK_VDDR_CORE_OV_CTRL_POK_TRIM_PROXY — POK trim bits. These bits are used to trim the comparator threshold voltage. See POK spec and efuse spec for details
0x1A130 CFG0_POK_VMON_EXT_MAIN1P8_UV_CTRL_PROXY reset 0x80000000 — Controls operation of the VMON_EXT_MAIN1P8 POK undervoltage detection
  [31] POK_VMON_EXT_MAIN1P8_UV_CTRL_HYST_EN_PROXY — Enable POK hysteresis
  [7] POK_VMON_EXT_MAIN1P8_UV_CTRL_OVER_VOLT_DET_PROXY — Over / under voltage detection mode 0 - Under voltage detection 1 - Over voltage detection
  [6:0] POK_VMON_EXT_MAIN1P8_UV_CTRL_POK_TRIM_PROXY — POK trim bits. These bits are used to trim the comparator threshold voltage. See POK spec and efuse spec for details
0x1A134 CFG0_POK_VMON_EXT_MAIN1P8_OV_CTRL_PROXY reset 0x80000000 — Controls operation of the VMON_EXT_MAIN1P8 POK overvoltage detection
  [31] POK_VMON_EXT_MAIN1P8_OV_CTRL_HYST_EN_PROXY — Enable POK hysteresis
  [7] POK_VMON_EXT_MAIN1P8_OV_CTRL_OVER_VOLT_DET_PROXY — Over / under voltage detection mode 0 - Under voltage detection 1 - Over voltage detection
  [6:0] POK_VMON_EXT_MAIN1P8_OV_CTRL_POK_TRIM_PROXY — POK trim bits. These bits are used to trim the comparator threshold voltage. See POK spec and efuse spec for details
0x1A138 CFG0_POK_VMON_EXT_MAIN3P3_UV_CTRL_PROXY reset 0x80000000 — Controls operation of the VMON_EXT_MAIN3P3 POK undervoltage detection
  [31] POK_VMON_EXT_MAIN3P3_UV_CTRL_HYST_EN_PROXY — Enable POK hysteresis
  [7] POK_VMON_EXT_MAIN3P3_UV_CTRL_OVER_VOLT_DET_PROXY — Over / under voltage detection mode 0 - Under voltage detection 1 - Over voltage detection
  [6:0] POK_VMON_EXT_MAIN3P3_UV_CTRL_POK_TRIM_PROXY — POK trim bits. These bits are used to trim the comparator threshold voltage. See POK spec and efuse spec for details
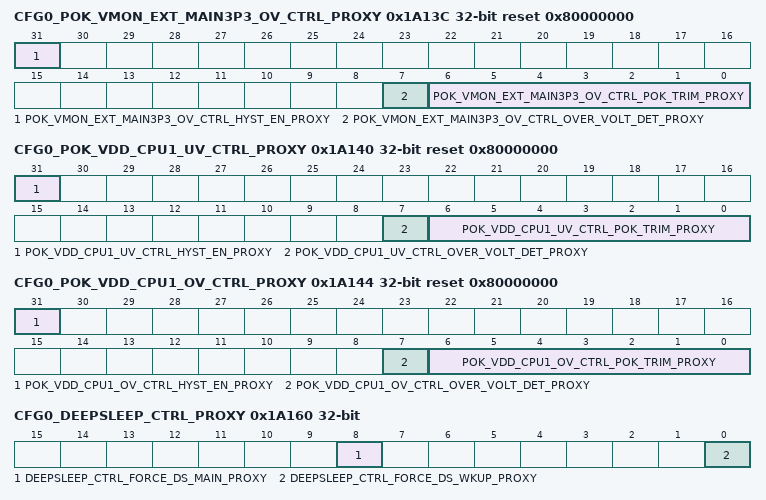
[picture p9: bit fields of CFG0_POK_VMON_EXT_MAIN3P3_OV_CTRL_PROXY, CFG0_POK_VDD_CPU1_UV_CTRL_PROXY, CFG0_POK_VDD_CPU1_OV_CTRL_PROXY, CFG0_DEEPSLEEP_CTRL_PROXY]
0x1A13C CFG0_POK_VMON_EXT_MAIN3P3_OV_CTRL_PROXY reset 0x80000000 — Controls operation of the VMON_EXT_MAIN3P3 POK overvoltage detection
  [31] POK_VMON_EXT_MAIN3P3_OV_CTRL_HYST_EN_PROXY — Enable POK hysteresis
  [7] POK_VMON_EXT_MAIN3P3_OV_CTRL_OVER_VOLT_DET_PROXY — Over / under voltage detection mode 0 - Under voltage detection 1 - Over voltage detection
  [6:0] POK_VMON_EXT_MAIN3P3_OV_CTRL_POK_TRIM_PROXY — POK trim bits. These bits are used to trim the comparator threshold voltage. See POK spec and efuse spec for details
0x1A140 CFG0_POK_VDD_CPU1_UV_CTRL_PROXY reset 0x80000000 — Controls operation of the VDD_DDR0 POK undervoltage detection
  [31] POK_VDD_CPU1_UV_CTRL_HYST_EN_PROXY — Enable POK hysteresis
  [7] POK_VDD_CPU1_UV_CTRL_OVER_VOLT_DET_PROXY — Over / under voltage detection mode 0 - Under voltage detection 1 - Over voltage detection
  [6:0] POK_VDD_CPU1_UV_CTRL_POK_TRIM_PROXY — POK trim bits. These bits are used to trim the comparator threshold voltage. See POK spec and efuse spec for details
0x1A144 CFG0_POK_VDD_CPU1_OV_CTRL_PROXY reset 0x80000000 — Controls operation of the VDD_DDR0 POK overvoltage detection
  [31] POK_VDD_CPU1_OV_CTRL_HYST_EN_PROXY — Enable POK hysteresis
  [7] POK_VDD_CPU1_OV_CTRL_OVER_VOLT_DET_PROXY — Over / under voltage detection mode 0 - Under voltage detection 1 - Over voltage detection
  [6:0] POK_VDD_CPU1_OV_CTRL_POK_TRIM_PROXY — POK trim bits. These bits are used to trim the comparator threshold voltage. See POK spec and efuse spec for details
0x1A160 CFG0_DEEPSLEEP_CTRL_PROXY — Used to control IO deepsleep operation
  [8] DEEPSLEEP_CTRL_FORCE_DS_MAIN_PROXY — Force all MAIN IOs into deepsleep mode when set
  [0] DEEPSLEEP_CTRL_FORCE_DS_WKUP_PROXY — Force all WKUP IOs into deepsleep mode when set
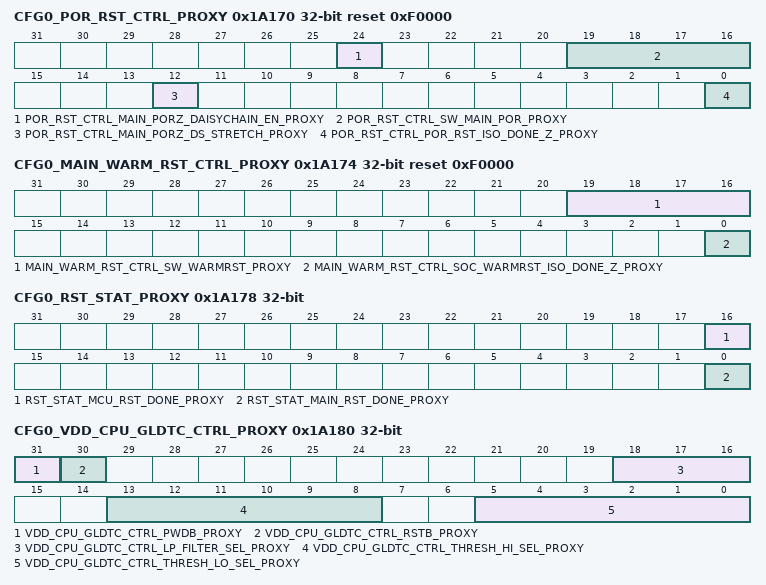
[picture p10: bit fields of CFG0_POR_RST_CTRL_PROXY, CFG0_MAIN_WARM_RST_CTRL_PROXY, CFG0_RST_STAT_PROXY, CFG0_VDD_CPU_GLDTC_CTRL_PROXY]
0x1A170 CFG0_POR_RST_CTRL_PROXY reset 0xF0000 — Controls MAIN domain power-on reset behavior.
  [24] POR_RST_CTRL_MAIN_PORZ_DAISYCHAIN_EN_PROXY — MAIN PORz daisy-chain event enable.Determines if MAIN PORz reset events affect daisy-chain wakeup 0 - DeepSleep MAIN PORz event is not part of daisy-chain 1 - DeepSleep MAIN PORz event is combined w/ other daisy chain events.
  [19:16] POR_RST_CTRL_SW_MAIN_POR_PROXY — Main Domain software power-on reset. When set to 4'b0110, a power-on is issued to the MAIN voltage domain. (Bits will reset to 4'b1111 on reset of the Main Domain)
  [12] POR_RST_CTRL_MAIN_PORZ_DS_STRETCH_PROXY — DeepSleep mode MAIN PORz stretch. 0 - No stretching 1 - Stretch the Main PORz event captured during DeepSleep mode
  [0] POR_RST_CTRL_POR_RST_ISO_DONE_Z_PROXY — Reset isolation completion (active low). This bit should be cleared only after reset isolation of the MAIN domain is complete. 0 - POR reset propagates to MAIN domain 1 - POR reset blocked from MAIN domain
0x1A174 CFG0_MAIN_WARM_RST_CTRL_PROXY reset 0xF0000 — Controls warm reset propagation to the MAIN domain. This allows the SMS to ensure that the MCU domain is properly isolated before the MAIN domain is reset.
  [19:16] MAIN_WARM_RST_CTRL_SW_WARMRST_PROXY — Main Domain software warm reset. When set to 4'b0110, a warm reset is issued to the MAIN voltage domain. (Bits will reset to 4'b1111 on reset of the Main Domain)
  [0] MAIN_WARM_RST_CTRL_SOC_WARMRST_ISO_DONE_Z_PROXY — Reset isolation completion (active low). This bit should be cleared only after reset isolation of the MAIN domain is complete. 0 - Warm reset propagates to MAIN domain 1 - Warm reset blocked from MAIN domain
0x1A178 CFG0_RST_STAT_PROXY ro — Shows the reset status
  [16] RST_STAT_MCU_RST_DONE_PROXY — Indicates MCU domain reset status. 0 - MCU domain is in reset 1 - MCU domain reset is complete
  [0] RST_STAT_MAIN_RST_DONE_PROXY — Indicates MAIN domain Warm reset status. 0 - MAIN domain is in Warm reset 1 - MAIN domain Warm reset is complete
0x1A17C CFG0_MCU_WARM_RST_CTRL_PROXY reset 0xF0000 — Controls warm reset propagation to the MCU domain. This allows the DMSC/SMS to ensure that the WKUP domain is properly isolated before the MCU domain is reset.
  [19:16] MCU_WARM_RST_CTRL_SW_WARMRST_PROXY — Chip software warm reset. When set to 4'b0110, a warm reset is issued to the device (all voltage domains). (Bits will reset to 4'b1111 on reset completion.)
0x1A180 CFG0_VDD_CPU_GLDTC_CTRL_PROXY — Controls the voltage glitch detector circuit monitoring the VDD_CPU voltage domain
  [31] VDD_CPU_GLDTC_CTRL_PWDB_PROXY — Power down - active low. 0 - Disable all functions 1 - Enable glitch detectors
  [30] VDD_CPU_GLDTC_CTRL_RSTB_PROXY — Reset - active low. To ensure proper operation, rstb must be not be de-asserted for at least 100 ns after power-up (pwdb de-asserted). Additionally, rstb must be toggled low at least 200 ns after any change in threshold or low-pass filter settings to prevent abnormal trigger events. 0 - Reset glitch detector flags 1 - Glitch detection flags are enabled
  [18:16] VDD_CPU_GLDTC_CTRL_LP_FILTER_SEL_PROXY — Selects the glitch detect low-pass filter bandwidth Field values (Others are reserved): 3'b000 - 150 kHz 3'b001 - 125 kHz 3'b010 - 100 kHz 3'b011 - 80 kHz 3'b100 - 60 kHz 3'b101 - 45 kHz 3'b110 - 30 kHz 3'b111 - 15 kHz
  [13:8] VDD_CPU_GLDTC_CTRL_THRESH_HI_SEL_PROXY — Selects the high voltage glitch threshold as a percentage of the monitored voltage Field values (Others are reserved): 6'b000000 - 93.5% of VDD 6'b000001 - 94.0% of VDD 6'b000010 - 94.5% of VDD 6'b000011 - 95.0% of VDD 6'b000100 - 95.5% of VDD 6'b000101 - 96.0% of VDD 6'b000110 - 96.5% of VDD 6'b000111 - 97.0% of VDD 6'b001000 - 97.5% of VDD 6'b001001 - 98.0% of VDD 6'b001010 - 98.5% of VDD 6'b001011 - 99.0% of VDD 6'b001100 - 99.5% of VDD 6'b001101 - 100.0% of VDD 6'b001110 - 100.5% of VDD 6'b001111 - 101.0% of VDD 6'b010000 - 101.5% of VDD 6'b010001 - 102.0% of VDD 6'b010010 - 102.5% of VDD 6'b010011 - 103.0% of VDD 6'b010100 - 103.5% of VDD 6'b010101 - 104.0% of VDD 6'b010110 - 104.5% of VDD 6'b010111 - 105.0% of VDD 6'b011000 - 105.5% of VDD 6'b011001 - 106.0% of VDD 6'b011010 - 106.5% of VDD 6'b011011 - 107.0% of VDD 6'b011100 - 107.5% of VDD 6'b011101 - 108.0% of VDD 6'b011110 - 108.5% of VDD 6'b011111 - 109.0% of VDD 6'b100000 - 109.5% of VDD 6'b100001 - 110.0% of VDD 6'b100010 - 111.0% of VDD 6'b100011 - 112.0% of VDD 6'b100100 - 113.0% of VDD 6'b100101 - 114.0% of VDD 6'b100110 - 115.0% of VDD 6'b100111 - 116.0% of VDD 6'b101000 - 117.0% of VDD 6'b101001 - 118.0% of VDD 6'b101010 - 119.0% of VDD 6'b101011 - 120.0% of VDD 6'b101100 - 121.0% of VDD 6'b101101 - 122.0% of VDD 6'b101110 - 123.0% of VDD 6'b101111 - 124.0% of VDD 6'b110000 - 125.0% of VDD 6'b110001 - 126.0% of VDD 6'b110010 - 127.0% of VDD 6'b110011 - 128.0% of VDD 6'b110100 - 129.0% of VDD 6'b110101 - 130.0% of VDD 6'b110110 - 131.0% of VDD 6'b110111 - 132.0% of VDD 6'b111000 - 133.0% of VDD 6'b111001 - 134.0% of VDD 6'b111010 - 135.0% of VDD 6'b111011 - 136.0% of VDD 6'b111100 - 137.0% of VDD 6'b111101 - 138.0% of VDD 6'b111110 - 139.0% of VDD 6'b111111 - 140.0% of VDD
  [5:0] VDD_CPU_GLDTC_CTRL_THRESH_LO_SEL_PROXY — Selects the low voltage glitch threshold as a percentage of the monitored voltage Field values (Others are reserved): 6'b000000 - 106.5% of VDD 6'b000001 - 106.0% of VDD 6'b000010 - 105.5% of VDD 6'b000011 - 105.0% of VDD 6'b000100 - 104.5% of VDD 6'b000101 - 104.0% of VDD 6'b000110 - 103.5% of VDD 6'b000111 - 103.0% of VDD 6'b001000 - 102.5% of VDD 6'b001001 - 102.0% of VDD 6'b001010 - 101.5% of VDD 6'b001011 - 101.0% of VDD 6'b001100 - 100.5% of VDD 6'b001101 - 100.0% of VDD 6'b001110 - 99.5% of VDD 6'b001111 - 99.0% of VDD 6'b010000 - 98.5% of VDD 6'b010001 - 98.0% of VDD 6'b010010 - 97.5% of VDD 6'b010011 - 97.0% of VDD 6'b010100 - 96.5% of VDD 6'b010101 - 96.0% of VDD 6'b010110 - 95.5% of VDD 6'b010111 - 95.0% of VDD 6'b011000 - 94.5% of VDD 6'b011001 - 94.0% of VDD 6'b011010 - 93.5% of VDD 6'b011011 - 93.0% of VDD 6'b011100 - 92.5% of VDD 6'b011101 - 92.0% of VDD 6'b011110 - 91.5% of VDD 6'b011111 - 91.0% of VDD 6'b100000 - 90.5% of VDD 6'b100001 - 90.0% of VDD 6'b100010 - 89.0% of VDD 6'b100011 - 88.0% of VDD 6'b100100 - 87.0% of VDD 6'b100101 - 86.0% of VDD 6'b100110 - 85.0% of VDD 6'b100111 - 84.0% of VDD 6'b101000 - 83.0% of VDD 6'b101001 - 82.0% of VDD 6'b101010 - 81.0% of VDD 6'b101011 - 80.0% of VDD 6'b101100 - 79.0% of VDD 6'b101101 - 78.0% of VDD 6'b101110 - 77.0% of VDD 6'b101111 - 76.0% of VDD 6'b110000 - 75.0% of VDD 6'b110001 - 74.0% of VDD 6'b110010 - 73.0% of VDD 6'b110011 - 72.0% of VDD 6'b110100 - 71.0% of VDD 6'b110101 - 70.0% of VDD 6'b110110 - 69.0% of VDD 6'b110111 - 68.0% of VDD 6'b111000 - 67.0% of VDD 6'b111001 - 66.0% of VDD 6'b111010 - 65.0% of VDD 6'b111011 - 64.0% of VDD 6'b111100 - 63.0% of VDD 6'b111101 - 62.0% of VDD 6'b111110 - 61.0% of VDD 6'b111111 - 60.0% of VDD
